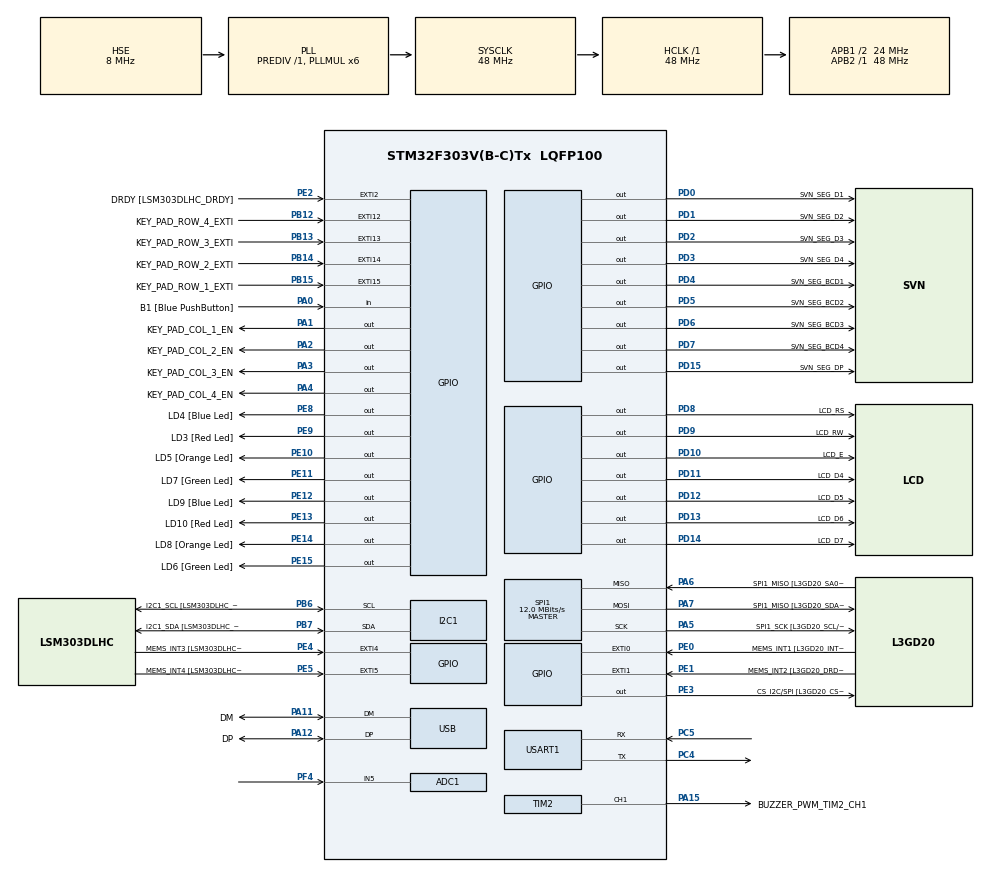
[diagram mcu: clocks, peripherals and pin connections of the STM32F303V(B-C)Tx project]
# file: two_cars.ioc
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ADC1.Channel-2\#ChannelRegularConversion=ADC_CHANNEL_5
ADC1.NbrOfConversionFlag=1
ADC1.Offset-2\#ChannelRegularConversion=0
ADC1.OffsetNumber-2\#ChannelRegularConversion=ADC_OFFSET_NONE
ADC1.Rank-2\#ChannelRegularConversion=1
ADC1.SamplingTime-2\#ChannelRegularConversion=ADC_SAMPLETIME_1CYCLE_5
ADC1.SamplingTimeOPAMP-2\#ChannelRegularConversion=ADC_SAMPLETIME_19CYCLES_5
ADC1.master=1
FREERTOS.Tasks01=defaultTask,0,128,StartDefaultTask,Default,NULL,Dynamic,NULL,NULL
FREERTOS.configGENERATE_RUN_TIME_STATS=1
FREERTOS.configRECORD_STACK_HIGH_ADDRESS=1
FREERTOS.configTOTAL_HEAP_SIZE=12288
FREERTOS.configUSE_STATS_FORMATTING_FUNCTIONS=1
FREERTOS.configUSE_TRACE_FACILITY=1
I2C1.Timing=0x00201D2B
I2C1.Timing-I2C=0x2000090E
Mcu.Family=STM32F3
Mcu.Name=STM32F303V(B-C)Tx
Mcu.Package=LQFP100
NVIC.ADC1_2_IRQn=true\:5\:0\:false\:false\:true\:true\:true\:true\:true
NVIC.EXTI15_10_IRQn=true\:5\:0\:false\:false\:true\:true\:true\:true\:true
NVIC.PriorityGroup=NVIC_PRIORITYGROUP_4
NVIC.TIM7_IRQn=true\:15\:0\:true\:false\:true\:false\:false\:true\:true
NVIC.TimeBase=TIM7_IRQn
NVIC.TimeBaseIP=TIM7
NVIC.USART1_IRQn=true\:5\:0\:false\:false\:true\:true\:true\:true\:true
PA0.GPIO_Label=B1 [Blue PushButton]
PA0.Signal=GPIO_Input
PA1.GPIO_Label=KEY_PAD_COL_1_EN
PA1.Signal=GPIO_Output
PA11.GPIO_Label=DM
PA11.Mode=Device
PA11.Signal=USB_DM
PA12.GPIO_Label=DP
PA12.Mode=Device
PA12.Signal=USB_DP
PA13.GPIO_Label=SWDIO
PA13.Mode=Trace_Asynchronous_SW
PA13.Signal=SYS_JTMS-SWDIO
PA14.GPIO_Label=SWCLK
PA14.Mode=Trace_Asynchronous_SW
PA14.Signal=SYS_JTCK-SWCLK
PA15.GPIO_Label=BUZZER_PWM_TIM2_CH1
PA15.Signal=S_TIM2_CH1_ETR
PA2.GPIO_Label=KEY_PAD_COL_2_EN
PA2.Signal=GPIO_Output
PA3.GPIO_Label=KEY_PAD_COL_3_EN
PA3.Signal=GPIO_Output
PA4.GPIO_Label=KEY_PAD_COL_4_EN
PA4.Signal=GPIO_Output
PA5.GPIO_Label=SPI1_SCK [L3GD20_SCL/SPC]
PA5.Mode=Full_Duplex_Master
PA5.Signal=SPI1_SCK
PA6.GPIO_Label=SPI1_MISO [L3GD20_SA0/SDO]
PA6.Mode=Full_Duplex_Master
PA6.Signal=SPI1_MISO
PA7.GPIO_Label=SPI1_MISO [L3GD20_SDA/SDI/SDO]
PA7.Mode=Full_Duplex_Master
PA7.Signal=SPI1_MOSI
PB12.GPIO_Label=KEY_PAD_ROW_4_EXTI
PB12.GPIO_PuPd=GPIO_PULLDOWN
PB12.Signal=GPXTI12
PB13.GPIO_Label=KEY_PAD_ROW_3_EXTI
PB13.GPIO_PuPd=GPIO_PULLDOWN
PB13.Signal=GPXTI13
PB14.GPIO_Label=KEY_PAD_ROW_2_EXTI
PB14.GPIO_PuPd=GPIO_PULLDOWN
PB14.Signal=GPXTI14
PB15.GPIO_Label=KEY_PAD_ROW_1_EXTI
PB15.GPIO_PuPd=GPIO_PULLDOWN
PB15.Signal=GPXTI15
PB3.GPIO_Label=SWO
PB3.Mode=Trace_Asynchronous_SW
PB3.Signal=SYS_JTDO-TRACESWO
PB6.GPIO_Label=I2C1_SCL [LSM303DLHC_SCL]
PB6.GPIO_Pu=GPIO_PULLUP
PB6.Mode=I2C
PB6.Signal=I2C1_SCL
PB7.GPIO_Label=I2C1_SDA [LSM303DLHC_SDA]
PB7.GPIO_Pu=GPIO_PULLUP
PB7.Mode=I2C
PB7.Signal=I2C1_SDA
PC14-OSC32_IN.GPIO_Label=OSC32_IN
PC14-OSC32_IN.Signal=RCC_OSC32_IN
PC15-OSC32_OUT.GPIO_Label=OSC32_OUT
PC15-OSC32_OUT.Signal=RCC_OSC32_OUT
PC4.Mode=Asynchronous
PC4.Signal=USART1_TX
PC5.Mode=Asynchronous
PC5.Signal=USART1_RX
PD0.GPIO_Label=SVN_SEG_D1
PD0.Signal=GPIO_Output
PD1.GPIO_Label=SVN_SEG_D2
PD1.Signal=GPIO_Output
PD10.GPIO_Label=LCD_E
PD10.GPIO_PuPd=GPIO_NOPULL
PD10.Signal=GPIO_Output
PD11.GPIO_Label=LCD_D4
PD11.GPIO_PuPd=GPIO_NOPULL
PD11.Signal=GPIO_Output
PD12.GPIO_Label=LCD_D5
PD12.GPIO_PuPd=GPIO_NOPULL
PD12.Signal=GPIO_Output
PD13.GPIO_Label=LCD_D6
PD13.GPIO_PuPd=GPIO_NOPULL
PD13.Signal=GPIO_Output
PD14.GPIO_Label=LCD_D7
PD14.GPIO_PuPd=GPIO_NOPULL
PD14.Signal=GPIO_Output
PD15.GPIO_Label=SVN_SEG_DP
PD15.Signal=GPIO_Output
PD2.GPIO_Label=SVN_SEG_D3
PD2.Signal=GPIO_Output
PD3.GPIO_Label=SVN_SEG_D4
PD3.Signal=GPIO_Output
PD4.GPIO_Label=SVN_SEG_BCD1
PD4.Signal=GPIO_Output
PD5.GPIO_Label=SVN_SEG_BCD2
PD5.Signal=GPIO_Output
PD6.GPIO_Label=SVN_SEG_BCD3
PD6.Signal=GPIO_Output
PD7.GPIO_Label=SVN_SEG_BCD4
PD7.Signal=GPIO_Output
PD8.GPIO_Label=LCD_RS
PD8.Signal=GPIO_Output
PD9.GPIO_Label=LCD_RW
PD9.GPIO_PuPd=GPIO_NOPULL
PD9.Signal=GPIO_Output
PE0.GPIO_Label=MEMS_INT1 [L3GD20_INT1]
PE0.GPIO_ModeDefaultEXTI=GPIO_MODE_EVT_RISING
PE0.Signal=GPXTI0
PE1.GPIO_Label=MEMS_INT2 [L3GD20_DRDY/INT2]
PE1.GPIO_ModeDefaultEXTI=GPIO_MODE_EVT_RISING
PE1.Signal=GPXTI1
PE10.GPIO_Label=LD5 [Orange Led]
PE10.Signal=GPIO_Output
PE11.GPIO_Label=LD7 [Green Led]
PE11.Signal=GPIO_Output
PE12.GPIO_Label=LD9 [Blue Led]
PE12.Signal=GPIO_Output
PE13.GPIO_Label=LD10 [Red Led]
PE13.Signal=GPIO_Output
PE14.GPIO_Label=LD8 [Orange Led]
PE14.Signal=GPIO_Output
PE15.GPIO_Label=LD6 [Green Led]
PE15.Signal=GPIO_Output
PE2.GPIO_Label=DRDY [LSM303DLHC_DRDY]
PE2.GPIO_ModeDefaultEXTI=GPIO_MODE_EVT_RISING
PE2.Signal=GPXTI2
PE3.GPIO_Label=CS_I2C/SPI [L3GD20_CS_I2C/SPI]
PE3.Signal=GPIO_Output
PE4.GPIO_Label=MEMS_INT3 [LSM303DLHC_INT1]
PE4.GPIO_ModeDefaultEXTI=GPIO_MODE_EVT_RISING
PE4.Signal=GPXTI4
PE5.GPIO_Label=MEMS_INT4 [LSM303DLHC_INT2]
PE5.GPIO_ModeDefaultEXTI=GPIO_MODE_EVT_RISING
PE5.Signal=GPXTI5
PE8.GPIO_Label=LD4 [Blue Led]
PE8.Signal=GPIO_Output
PE9.GPIO_Label=LD3 [Red Led]
PE9.Signal=GPIO_Output
PF0-OSC_IN.GPIO_Label=OSC_IN
PF0-OSC_IN.Mode=HSE-External-Clock-Source
PF0-OSC_IN.Signal=RCC_OSC_IN
PF1-OSC_OUT.GPIO_Label=OSC_OUT
PF1-OSC_OUT.Signal=RCC_OSC_OUT
PF4.Mode=IN5-Single-Ended
PF4.Signal=ADC1_IN5
ProjectManager.HeapSize=0x200
ProjectManager.StackSize=0x400
ProjectManager.TargetToolchain=Makefile
RCC.AHBFreq_Value=48000000
RCC.APB1CLKDivider=RCC_HCLK_DIV2
RCC.APB1Freq_Value=24000000
RCC.APB1TimFreq_Value=48000000
RCC.APB2Freq_Value=48000000
RCC.APB2TimFreq_Value=48000000
RCC.CortexFreq_Value=48000000
RCC.HCLKFreq_Value=48000000
RCC.HSE_VALUE=8000000
RCC.HSI_VALUE=8000000
RCC.LSE_VALUE=32768
RCC.PLLMUL=RCC_PLL_MUL6
RCC.SYSCLKFreq_VALUE=48000000
RCC.SYSCLKSourceVirtual=RCC_SYSCLKSOURCE_PLLCLK
RCC.USBFreq_Value=48000000
RTC.AsynchPrediv=40
RTC.Format=RTC_FORMAT_BCD
RTC.SynchPrediv=1000
SH.S_TIM2_CH1_ETR.0=TIM2_CH1,PWM Generation1 CH1
SPI1.BaudRatePrescaler=SPI_BAUDRATEPRESCALER_4
SPI1.BaudRatePrescaler-Full_Duplex_Master=SPI_BAUDRATEPRESCALER_2
SPI1.CalculateBaudRate=12.0 MBits/s
SPI1.CalculateBaudRate-Full_Duplex_Master=24.0 MBits/s
SPI1.Direction=SPI_DIRECTION_2LINES
SPI1.Mode=SPI_MODE_MASTER
SPI1.Mode-Full_Duplex_Master=SPI_MODE_MASTER
SPI1.VirtualType=VM_MASTER
TIM2.Channel-PWM\ Generation1\ CH1=TIM_CHANNEL_1
USART1.VirtualMode-Asynchronous=VM_ASYNC
VP_FREERTOS_VS_CMSIS_V1.Mode=CMSIS_V1
VP_RTC_VS_RTC_Activate.Mode=RTC_Enabled
VP_RTC_VS_RTC_Calendar.Mode=RTC_Calendar
VP_SYS_VS_tim7.Mode=TIM7
board=STM32F3DISCOVERY

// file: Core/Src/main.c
/* USER CODE BEGIN Header */
/**
 ******************************************************************************
 * @file           : main.c
 * @brief          : Main program body
 ******************************************************************************
 * @attention
 *
 * Copyright (c) 2025 STMicroelectronics.
 * All rights reserved.
 *
 * This software is licensed under terms that can be found in the LICENSE file
 * in the root directory of this software component.
 * If no LICENSE file comes with this software, it is provided AS-IS.
 *
 ******************************************************************************
 */
/* USER CODE END Header */
#include "main.h"
#include "cmsis_os.h"

/* USER CODE BEGIN Includes */
#include <stdbool.h>
#include "entry.h"
/* USER CODE END Includes */

ADC_HandleTypeDef hadc1;

I2C_HandleTypeDef hi2c1;

RTC_HandleTypeDef hrtc;

SPI_HandleTypeDef hspi1;

TIM_HandleTypeDef htim2;

UART_HandleTypeDef huart1;

PCD_HandleTypeDef hpcd_USB_FS;

osThreadId defaultTaskHandle;

void SystemClock_Config(void);
static void MX_GPIO_Init(void);
static void MX_I2C1_Init(void);
static void MX_SPI1_Init(void);
static void MX_USB_PCD_Init(void);
static void MX_USART1_UART_Init(void);
static void MX_RTC_Init(void);
static void MX_TIM2_Init(void);
static void MX_ADC1_Init(void);
void StartDefaultTask(void const * argument);

int main(void)
{

  /* MCU Configuration--------------------------------------------------------*/

  /* Reset of all peripherals, Initializes the Flash interface and the Systick. */
  HAL_Init();

  /* Configure the system clock */
  SystemClock_Config();

  /* Initialize all configured peripherals */
  MX_GPIO_Init();
  MX_I2C1_Init();
  MX_SPI1_Init();
  MX_USB_PCD_Init();
  MX_USART1_UART_Init();
  MX_RTC_Init();
  MX_TIM2_Init();
  MX_ADC1_Init();

  /* USER CODE BEGIN RTOS_QUEUES */
  /* add queues, ... */
  // ! this section will get jumped over
  // ! do not add anything here !!!
  if (false) {
  /* USER CODE END RTOS_QUEUES */

  /* Create the thread(s) */
  /* definition and creation of defaultTask */
  osThreadDef(defaultTask, StartDefaultTask, osPriorityNormal, 0, 128);
  defaultTaskHandle = osThreadCreate(osThread(defaultTask), NULL);

  /* USER CODE BEGIN RTOS_THREADS */
    /* add threads, ... */
  }
  setup();
  /* USER CODE END RTOS_THREADS */

  /* Start scheduler */
  osKernelStart();

  /* We should never get here as control is now taken by the scheduler */

  /* Infinite loop */
  while (1) {

  }
}

void SystemClock_Config(void)
{
  RCC_OscInitTypeDef RCC_OscInitStruct = {0};
  RCC_ClkInitTypeDef RCC_ClkInitStruct = {0};
  RCC_PeriphCLKInitTypeDef PeriphClkInit = {0};

  /** Initializes the RCC Oscillators according to the specified parameters
  * in the RCC_OscInitTypeDef structure.
  */
  RCC_OscInitStruct.OscillatorType = RCC_OSCILLATORTYPE_HSI|RCC_OSCILLATORTYPE_LSI
                              |RCC_OSCILLATORTYPE_HSE;
  RCC_OscInitStruct.HSEState = RCC_HSE_BYPASS;
  RCC_OscInitStruct.HSEPredivValue = RCC_HSE_PREDIV_DIV1;
  RCC_OscInitStruct.HSIState = RCC_HSI_ON;
  RCC_OscInitStruct.HSICalibrationValue = RCC_HSICALIBRATION_DEFAULT;
  RCC_OscInitStruct.LSIState = RCC_LSI_ON;
  RCC_OscInitStruct.PLL.PLLState = RCC_PLL_ON;
  RCC_OscInitStruct.PLL.PLLSource = RCC_PLLSOURCE_HSE;
  RCC_OscInitStruct.PLL.PLLMUL = RCC_PLL_MUL6;
  if (HAL_RCC_OscConfig(&RCC_OscInitStruct) != HAL_OK)
  {
    Error_Handler();
  }

  /** Initializes the CPU, AHB and APB buses clocks
  */
  RCC_ClkInitStruct.ClockType = RCC_CLOCKTYPE_HCLK|RCC_CLOCKTYPE_SYSCLK
                              |RCC_CLOCKTYPE_PCLK1|RCC_CLOCKTYPE_PCLK2;
  RCC_ClkInitStruct.SYSCLKSource = RCC_SYSCLKSOURCE_PLLCLK;
  RCC_ClkInitStruct.AHBCLKDivider = RCC_SYSCLK_DIV1;
  RCC_ClkInitStruct.APB1CLKDivider = RCC_HCLK_DIV2;
  RCC_ClkInitStruct.APB2CLKDivider = RCC_HCLK_DIV1;

  if (HAL_RCC_ClockConfig(&RCC_ClkInitStruct, FLASH_LATENCY_1) != HAL_OK)
  {
    Error_Handler();
  }
  PeriphClkInit.PeriphClockSelection = RCC_PERIPHCLK_USB|RCC_PERIPHCLK_USART1
                              |RCC_PERIPHCLK_I2C1|RCC_PERIPHCLK_RTC
                              |RCC_PERIPHCLK_ADC12;
  PeriphClkInit.Usart1ClockSelection = RCC_USART1CLKSOURCE_PCLK2;
  PeriphClkInit.Adc12ClockSelection = RCC_ADC12PLLCLK_DIV1;
  PeriphClkInit.I2c1ClockSelection = RCC_I2C1CLKSOURCE_HSI;
  PeriphClkInit.RTCClockSelection = RCC_RTCCLKSOURCE_LSI;
  PeriphClkInit.USBClockSelection = RCC_USBCLKSOURCE_PLL;
  if (HAL_RCCEx_PeriphCLKConfig(&PeriphClkInit) != HAL_OK)
  {
    Error_Handler();
  }
}

static void MX_ADC1_Init(void)
{

  ADC_MultiModeTypeDef multimode = {0};
  ADC_ChannelConfTypeDef sConfig = {0};

  /** Common config
  */
  hadc1.Instance = ADC1;
  hadc1.Init.ClockPrescaler = ADC_CLOCK_ASYNC_DIV1;
  hadc1.Init.Resolution = ADC_RESOLUTION_12B;
  hadc1.Init.ScanConvMode = ADC_SCAN_DISABLE;
  hadc1.Init.ContinuousConvMode = DISABLE;
  hadc1.Init.DiscontinuousConvMode = DISABLE;
  hadc1.Init.ExternalTrigConvEdge = ADC_EXTERNALTRIGCONVEDGE_NONE;
  hadc1.Init.ExternalTrigConv = ADC_SOFTWARE_START;
  hadc1.Init.DataAlign = ADC_DATAALIGN_RIGHT;
  hadc1.Init.NbrOfConversion = 1;
  hadc1.Init.DMAContinuousRequests = DISABLE;
  hadc1.Init.EOCSelection = ADC_EOC_SINGLE_CONV;
  hadc1.Init.LowPowerAutoWait = DISABLE;
  hadc1.Init.Overrun = ADC_OVR_DATA_OVERWRITTEN;
  if (HAL_ADC_Init(&hadc1) != HAL_OK)
  {
    Error_Handler();
  }

  /** Configure the ADC multi-mode
  */
  multimode.Mode = ADC_MODE_INDEPENDENT;
  if (HAL_ADCEx_MultiModeConfigChannel(&hadc1, &multimode) != HAL_OK)
  {
    Error_Handler();
  }

  /** Configure Regular Channel
  */
  sConfig.Channel = ADC_CHANNEL_5;
  sConfig.Rank = ADC_REGULAR_RANK_1;
  sConfig.SingleDiff = ADC_SINGLE_ENDED;
  sConfig.SamplingTime = ADC_SAMPLETIME_1CYCLE_5;
  sConfig.OffsetNumber = ADC_OFFSET_NONE;
  sConfig.Offset = 0;
  if (HAL_ADC_ConfigChannel(&hadc1, &sConfig) != HAL_OK)
  {
    Error_Handler();
  }

}

static void MX_I2C1_Init(void)
{

  hi2c1.Instance = I2C1;
  hi2c1.Init.Timing = 0x00201D2B;
  hi2c1.Init.OwnAddress1 = 0;
  hi2c1.Init.AddressingMode = I2C_ADDRESSINGMODE_7BIT;
  hi2c1.Init.DualAddressMode = I2C_DUALADDRESS_DISABLE;
  hi2c1.Init.OwnAddress2 = 0;
  hi2c1.Init.OwnAddress2Masks = I2C_OA2_NOMASK;
  hi2c1.Init.GeneralCallMode = I2C_GENERALCALL_DISABLE;
  hi2c1.Init.NoStretchMode = I2C_NOSTRETCH_DISABLE;
  if (HAL_I2C_Init(&hi2c1) != HAL_OK)
  {
    Error_Handler();
  }

  /** Configure Analogue filter
  */
  if (HAL_I2CEx_ConfigAnalogFilter(&hi2c1, I2C_ANALOGFILTER_ENABLE) != HAL_OK)
  {
    Error_Handler();
  }

  /** Configure Digital filter
  */
  if (HAL_I2CEx_ConfigDigitalFilter(&hi2c1, 0) != HAL_OK)
  {
    Error_Handler();
  }

}

static void MX_RTC_Init(void)
{

  RTC_TimeTypeDef sTime = {0};
  RTC_DateTypeDef sDate = {0};

  /** Initialize RTC Only
  */
  hrtc.Instance = RTC;
  hrtc.Init.HourFormat = RTC_HOURFORMAT_24;
  hrtc.Init.AsynchPrediv = 40;
  hrtc.Init.SynchPrediv = 1000;
  hrtc.Init.OutPut = RTC_OUTPUT_DISABLE;
  hrtc.Init.OutPutPolarity = RTC_OUTPUT_POLARITY_HIGH;
  hrtc.Init.OutPutType = RTC_OUTPUT_TYPE_OPENDRAIN;
  if (HAL_RTC_Init(&hrtc) != HAL_OK)
  {
    Error_Handler();
  }

  /** Initialize RTC and set the Time and Date
  */
  sTime.Hours = 0x0;
  sTime.Minutes = 0x0;
  sTime.Seconds = 0x0;
  sTime.DayLightSaving = RTC_DAYLIGHTSAVING_NONE;
  sTime.StoreOperation = RTC_STOREOPERATION_RESET;
  if (HAL_RTC_SetTime(&hrtc, &sTime, RTC_FORMAT_BCD) != HAL_OK)
  {
    Error_Handler();
  }
  sDate.WeekDay = RTC_WEEKDAY_MONDAY;
  sDate.Month = RTC_MONTH_JANUARY;
  sDate.Date = 0x1;
  sDate.Year = 0x0;

  if (HAL_RTC_SetDate(&hrtc, &sDate, RTC_FORMAT_BCD) != HAL_OK)
  {
    Error_Handler();
  }

}

static void MX_SPI1_Init(void)
{

  /* SPI1 parameter configuration*/
  hspi1.Instance = SPI1;
  hspi1.Init.Mode = SPI_MODE_MASTER;
  hspi1.Init.Direction = SPI_DIRECTION_2LINES;
  hspi1.Init.DataSize = SPI_DATASIZE_4BIT;
  hspi1.Init.CLKPolarity = SPI_POLARITY_LOW;
  hspi1.Init.CLKPhase = SPI_PHASE_1EDGE;
  hspi1.Init.NSS = SPI_NSS_SOFT;
  hspi1.Init.BaudRatePrescaler = SPI_BAUDRATEPRESCALER_4;
  hspi1.Init.FirstBit = SPI_FIRSTBIT_MSB;
  hspi1.Init.TIMode = SPI_TIMODE_DISABLE;
  hspi1.Init.CRCCalculation = SPI_CRCCALCULATION_DISABLE;
  hspi1.Init.CRCPolynomial = 7;
  hspi1.Init.CRCLength = SPI_CRC_LENGTH_DATASIZE;
  hspi1.Init.NSSPMode = SPI_NSS_PULSE_ENABLE;
  if (HAL_SPI_Init(&hspi1) != HAL_OK)
  {
    Error_Handler();
  }

}

static void MX_TIM2_Init(void)
{

  TIM_MasterConfigTypeDef sMasterConfig = {0};
  TIM_OC_InitTypeDef sConfigOC = {0};

  htim2.Instance = TIM2;
  htim2.Init.Prescaler = 0;
  htim2.Init.CounterMode = TIM_COUNTERMODE_UP;
  htim2.Init.Period = 4294967295;
  htim2.Init.ClockDivision = TIM_CLOCKDIVISION_DIV1;
  htim2.Init.AutoReloadPreload = TIM_AUTORELOAD_PRELOAD_DISABLE;
  if (HAL_TIM_PWM_Init(&htim2) != HAL_OK)
  {
    Error_Handler();
  }
  sMasterConfig.MasterOutputTrigger = TIM_TRGO_RESET;
  sMasterConfig.MasterSlaveMode = TIM_MASTERSLAVEMODE_DISABLE;
  if (HAL_TIMEx_MasterConfigSynchronization(&htim2, &sMasterConfig) != HAL_OK)
  {
    Error_Handler();
  }
  sConfigOC.OCMode = TIM_OCMODE_PWM1;
  sConfigOC.Pulse = 0;
  sConfigOC.OCPolarity = TIM_OCPOLARITY_HIGH;
  sConfigOC.OCFastMode = TIM_OCFAST_DISABLE;
  if (HAL_TIM_PWM_ConfigChannel(&htim2, &sConfigOC, TIM_CHANNEL_1) != HAL_OK)
  {
    Error_Handler();
  }
  HAL_TIM_MspPostInit(&htim2);

}

static void MX_USART1_UART_Init(void)
{

  huart1.Instance = USART1;
  huart1.Init.BaudRate = 38400;
  huart1.Init.WordLength = UART_WORDLENGTH_8B;
  huart1.Init.StopBits = UART_STOPBITS_1;
  huart1.Init.Parity = UART_PARITY_NONE;
  huart1.Init.Mode = UART_MODE_TX_RX;
  huart1.Init.HwFlowCtl = UART_HWCONTROL_NONE;
  huart1.Init.OverSampling = UART_OVERSAMPLING_16;
  huart1.Init.OneBitSampling = UART_ONE_BIT_SAMPLE_DISABLE;
  huart1.AdvancedInit.AdvFeatureInit = UART_ADVFEATURE_NO_INIT;
  if (HAL_UART_Init(&huart1) != HAL_OK)
  {
    Error_Handler();
  }

}

static void MX_USB_PCD_Init(void)
{

  hpcd_USB_FS.Instance = USB;
  hpcd_USB_FS.Init.dev_endpoints = 8;
  hpcd_USB_FS.Init.speed = PCD_SPEED_FULL;
  hpcd_USB_FS.Init.phy_itface = PCD_PHY_EMBEDDED;
  hpcd_USB_FS.Init.low_power_enable = DISABLE;
  hpcd_USB_FS.Init.battery_charging_enable = DISABLE;
  if (HAL_PCD_Init(&hpcd_USB_FS) != HAL_OK)
  {
    Error_Handler();
  }

}

static void MX_GPIO_Init(void)
{
  GPIO_InitTypeDef GPIO_InitStruct = {0};

  /* GPIO Ports Clock Enable */
  __HAL_RCC_GPIOE_CLK_ENABLE();
  __HAL_RCC_GPIOC_CLK_ENABLE();
  __HAL_RCC_GPIOF_CLK_ENABLE();
  __HAL_RCC_GPIOA_CLK_ENABLE();
  __HAL_RCC_GPIOB_CLK_ENABLE();
  __HAL_RCC_GPIOD_CLK_ENABLE();

  /*Configure GPIO pin Output Level */
  HAL_GPIO_WritePin(GPIOE, CS_I2C_SPI_Pin|LD4_Pin|LD3_Pin|LD5_Pin
                          |LD7_Pin|LD9_Pin|LD10_Pin|LD8_Pin
                          |LD6_Pin, GPIO_PIN_RESET);

  /*Configure GPIO pin Output Level */
  HAL_GPIO_WritePin(GPIOA, KEY_PAD_COL_1_EN_Pin|KEY_PAD_COL_2_EN_Pin|KEY_PAD_COL_3_EN_Pin|KEY_PAD_COL_4_EN_Pin, GPIO_PIN_RESET);

  /*Configure GPIO pin Output Level */
  HAL_GPIO_WritePin(GPIOD, LCD_RS_Pin|LCD_RW_Pin|LCD_E_Pin|LCD_D4_Pin
                          |LCD_D5_Pin|LCD_D6_Pin|LCD_D7_Pin|SVN_SEG_DP_Pin
                          |SVN_SEG_D1_Pin|SVN_SEG_D2_Pin|SVN_SEG_D3_Pin|SVN_SEG_D4_Pin
                          |SVN_SEG_BCD1_Pin|SVN_SEG_BCD2_Pin|SVN_SEG_BCD3_Pin|SVN_SEG_BCD4_Pin, GPIO_PIN_RESET);

  /*Configure GPIO pins : DRDY_Pin MEMS_INT3_Pin MEMS_INT4_Pin MEMS_INT1_Pin
                           MEMS_INT2_Pin */
  GPIO_InitStruct.Pin = DRDY_Pin|MEMS_INT3_Pin|MEMS_INT4_Pin|MEMS_INT1_Pin
                          |MEMS_INT2_Pin;
  GPIO_InitStruct.Mode = GPIO_MODE_EVT_RISING;
  GPIO_InitStruct.Pull = GPIO_NOPULL;
  HAL_GPIO_Init(GPIOE, &GPIO_InitStruct);

  /*Configure GPIO pins : CS_I2C_SPI_Pin LD4_Pin LD3_Pin LD5_Pin
                           LD7_Pin LD9_Pin LD10_Pin LD8_Pin
                           LD6_Pin */
  GPIO_InitStruct.Pin = CS_I2C_SPI_Pin|LD4_Pin|LD3_Pin|LD5_Pin
                          |LD7_Pin|LD9_Pin|LD10_Pin|LD8_Pin
                          |LD6_Pin;
  GPIO_InitStruct.Mode = GPIO_MODE_OUTPUT_PP;
  GPIO_InitStruct.Pull = GPIO_NOPULL;
  GPIO_InitStruct.Speed = GPIO_SPEED_FREQ_LOW;
  HAL_GPIO_Init(GPIOE, &GPIO_InitStruct);

  /*Configure GPIO pin : B1_Pin */
  GPIO_InitStruct.Pin = B1_Pin;
  GPIO_InitStruct.Mode = GPIO_MODE_INPUT;
  GPIO_InitStruct.Pull = GPIO_NOPULL;
  HAL_GPIO_Init(B1_GPIO_Port, &GPIO_InitStruct);

  /*Configure GPIO pins : KEY_PAD_COL_1_EN_Pin KEY_PAD_COL_2_EN_Pin KEY_PAD_COL_3_EN_Pin KEY_PAD_COL_4_EN_Pin */
  GPIO_InitStruct.Pin = KEY_PAD_COL_1_EN_Pin|KEY_PAD_COL_2_EN_Pin|KEY_PAD_COL_3_EN_Pin|KEY_PAD_COL_4_EN_Pin;
  GPIO_InitStruct.Mode = GPIO_MODE_OUTPUT_PP;
  GPIO_InitStruct.Pull = GPIO_NOPULL;
  GPIO_InitStruct.Speed = GPIO_SPEED_FREQ_LOW;
  HAL_GPIO_Init(GPIOA, &GPIO_InitStruct);

  /*Configure GPIO pins : KEY_PAD_ROW_4_EXTI_Pin KEY_PAD_ROW_3_EXTI_Pin KEY_PAD_ROW_2_EXTI_Pin KEY_PAD_ROW_1_EXTI_Pin */
  GPIO_InitStruct.Pin = KEY_PAD_ROW_4_EXTI_Pin|KEY_PAD_ROW_3_EXTI_Pin|KEY_PAD_ROW_2_EXTI_Pin|KEY_PAD_ROW_1_EXTI_Pin;
  GPIO_InitStruct.Mode = GPIO_MODE_IT_RISING;
  GPIO_InitStruct.Pull = GPIO_PULLDOWN;
  HAL_GPIO_Init(GPIOB, &GPIO_InitStruct);

  /*Configure GPIO pins : LCD_RS_Pin LCD_RW_Pin LCD_E_Pin LCD_D4_Pin
                           LCD_D5_Pin LCD_D6_Pin LCD_D7_Pin SVN_SEG_DP_Pin
                           SVN_SEG_D1_Pin SVN_SEG_D2_Pin SVN_SEG_D3_Pin SVN_SEG_D4_Pin
                           SVN_SEG_BCD1_Pin SVN_SEG_BCD2_Pin SVN_SEG_BCD3_Pin SVN_SEG_BCD4_Pin */
  GPIO_InitStruct.Pin = LCD_RS_Pin|LCD_RW_Pin|LCD_E_Pin|LCD_D4_Pin
                          |LCD_D5_Pin|LCD_D6_Pin|LCD_D7_Pin|SVN_SEG_DP_Pin
                          |SVN_SEG_D1_Pin|SVN_SEG_D2_Pin|SVN_SEG_D3_Pin|SVN_SEG_D4_Pin
                          |SVN_SEG_BCD1_Pin|SVN_SEG_BCD2_Pin|SVN_SEG_BCD3_Pin|SVN_SEG_BCD4_Pin;
  GPIO_InitStruct.Mode = GPIO_MODE_OUTPUT_PP;
  GPIO_InitStruct.Pull = GPIO_NOPULL;
  GPIO_InitStruct.Speed = GPIO_SPEED_FREQ_LOW;
  HAL_GPIO_Init(GPIOD, &GPIO_InitStruct);

  /* EXTI interrupt init*/
  HAL_NVIC_SetPriority(EXTI15_10_IRQn, 5, 0);
  HAL_NVIC_EnableIRQ(EXTI15_10_IRQn);

}

void StartDefaultTask(void const * argument)
{
  for (;;) {
    osDelay(1);
  }
}

void HAL_TIM_PeriodElapsedCallback(TIM_HandleTypeDef *htim)
{
  if (htim->Instance == TIM7) {
    HAL_IncTick();
  }
}

void Error_Handler(void)
{
  __disable_irq();
  while (1) {
  }
}

#ifdef  USE_FULL_ASSERT
/**
  * @brief  Reports the name of the source file and the source line number
  *         where the assert_param error has occurred.
  * @param  file: pointer to the source file name
  * @param  line: assert_param error line source number
  * @retval None
  */
void assert_failed(uint8_t *file, uint32_t line)
{
  /* USER CODE BEGIN 6 */
  /* User can add his own implementation to report the file name and line
     number, ex: printf("Wrong parameters value: file %s on line %d\r\n", file,
     line) */
  /* USER CODE END 6 */
}
#endif /* USE_FULL_ASSERT */

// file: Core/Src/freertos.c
/* USER CODE BEGIN Header */
/**
  ******************************************************************************
  * File Name          : freertos.c
  * Description        : Code for freertos applications
  ******************************************************************************
  * @attention
  *
  * Copyright (c) 2025 STMicroelectronics.
  * All rights reserved.
  *
  * This software is licensed under terms that can be found in the LICENSE file
  * in the root directory of this software component.
  * If no LICENSE file comes with this software, it is provided AS-IS.
  *
  ******************************************************************************
  */
/* USER CODE END Header */

#include "FreeRTOS.h"
#include "task.h"
#include "main.h"

/* GetIdleTaskMemory prototype (linked to static allocation support) */
void vApplicationGetIdleTaskMemory( StaticTask_t **ppxIdleTaskTCBBuffer, StackType_t **ppxIdleTaskStackBuffer, uint32_t *pulIdleTaskStackSize );

/* Hook prototypes */
void configureTimerForRunTimeStats(void);
unsigned long getRunTimeCounterValue(void);

/* USER CODE BEGIN 1 */
/* Functions needed when configGENERATE_RUN_TIME_STATS is on */
__weak void configureTimerForRunTimeStats(void)
{

}

__weak unsigned long getRunTimeCounterValue(void)
{
return 0;
}
/* USER CODE END 1 */

/* USER CODE BEGIN GET_IDLE_TASK_MEMORY */
static StaticTask_t xIdleTaskTCBBuffer;
static StackType_t xIdleStack[configMINIMAL_STACK_SIZE];

void vApplicationGetIdleTaskMemory( StaticTask_t **ppxIdleTaskTCBBuffer, StackType_t **ppxIdleTaskStackBuffer, uint32_t *pulIdleTaskStackSize )
{
  *ppxIdleTaskTCBBuffer = &xIdleTaskTCBBuffer;
  *ppxIdleTaskStackBuffer = &xIdleStack[0];
  *pulIdleTaskStackSize = configMINIMAL_STACK_SIZE;
  /* place for user code */
}
/* USER CODE END GET_IDLE_TASK_MEMORY */
